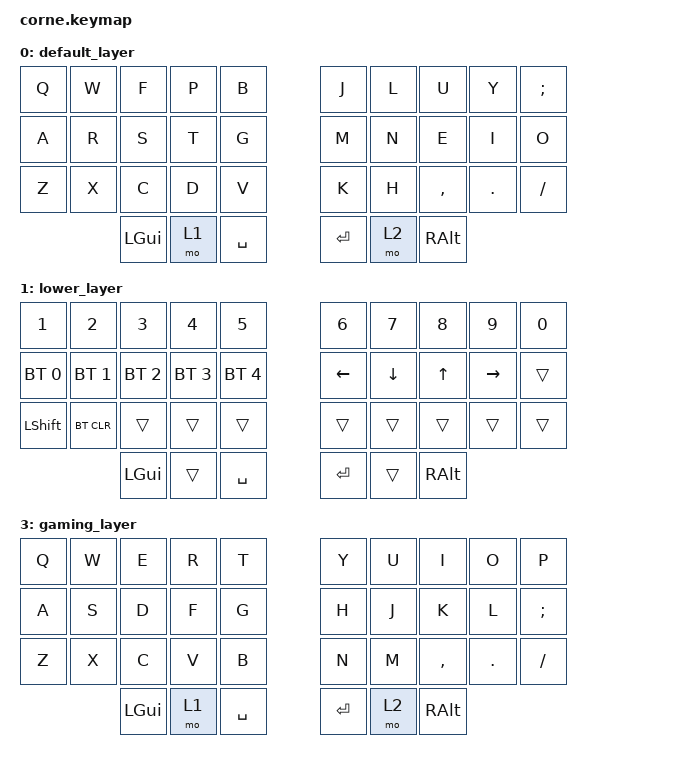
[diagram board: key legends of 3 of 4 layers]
/*
 * Copyright (c) 2020 The ZMK Contributors
 *
 * SPDX-License-Identifier: MIT
 */

#include <behaviors.dtsi>
#include <dt-bindings/zmk/keys.h>
#include <dt-bindings/zmk/bt.h>

/ {
        chosen { 
                zmk,physical-layout = &foostan_corne_5col_layout; };
        keymap {
                compatible = "zmk,keymap";

                default_layer {
// -----------------------------------------------------------------------------------------
// |  Q  |  W  |  F  |  P  |  B  |   |  J  |  L   |  U  |  Y  |  ;  |
// |  A  |  R  |  S  |  T  |  G  |   |  M  |  N   |  E  |  I  |  O  |
// |  Z  |  X  |  C  |  D  |  V  |   |  K  |  H   |  ,  |  .  |  /  |
//             | GUI | LWR | SPC |   | ENT | RSE  | ALT |
                        bindings = <
     &kp Q &kp W &kp F &kp P &kp B   &kp J &kp L  &kp U     &kp Y   &kp SEMI
     &kp A &kp R &kp S &kp T &kp G   &kp M &kp N  &kp E     &kp I   &kp O
     &kp Z &kp X &kp C &kp D &kp V   &kp K &kp H  &kp COMMA &kp DOT &kp FSLH
          &kp LGUI &mo 1 &kp SPACE   &kp RET &mo 2 &kp RALT
                        >;
                };
                lower_layer {
// -----------------------------------------------------------------------------------------
// |  1   |  2  |  3  |  4  |  5  |     |   |  6  |  7  |  8  |  9  |  0  |
// | BTCLR| BT1 | BT2 | BT3 | BT4 | BT5 |   | LFT | DWN |  UP | RGT |     |
// | SHFT |     |     |     |     |     |   |     |     |     |     |     |
//                    | GUI |     | SPC |   | ENT |     | ALT |
                        bindings = <
   &kp N1       &kp N2       &kp N3       &kp N4       &kp N5         &kp N6   &kp N7   &kp N8 &kp N9    &kp N0 
   &bt BT_SEL 0 &bt BT_SEL 1 &bt BT_SEL 2 &bt BT_SEL 3 &bt BT_SEL 4   &kp LEFT &kp DOWN &kp UP &kp RIGHT &trans
   &kp LSHIFT	&bt BT_CLR         &trans       &trans       &trans       &trans         &trans   &trans   &trans &trans
                                    &kp LGUI     &trans       &kp SPACE      &kp RET  &trans   &kp RALT
                        >;
                };

                raise_layer {
// -----------------------------------------------------------------------------------------
// |  !  |  @  |  #  |  $  |  %  |   |  ^  |  &  |  *  |  (  |  )  |
// |     |     |     |     |     |   |  -  |  =  |  [  |  ]  |  \  |
// |     |     |     |     |     |   |  _  |  +  |  {  |  }  | "|" |
//                    | GUI |     | SPC |   | ENT |     | ALT |
                        bindings = <
   &kp EXCL &kp AT &kp HASH &kp DLLR &kp PRCNT   &kp CARET &kp AMPS  &kp ASTRK &kp LPAR &kp RPAR &kp BSPC
   &trans   &trans &trans   &trans   &trans      &kp MINUS &kp EQUAL &kp LBKT  &kp RBKT &kp BSLH &kp GRAVE
   &trans   &trans &trans   &trans   &trans      &kp UNDER &kp PLUS  &kp LBRC  &kp RBRC &kp PIPE &kp TILDE
                   &kp LGUI &trans   &kp SPACE   &kp RET   &trans    &kp RALT
                        >;
                };
                gaming_layer {
// -----------------------------------------------------------------------------------------
// |  Q  |  W  |  E  |  R  |  T  |   |  Y  |  U   |  I  |  O  |  P  |
// |  A  |  S  |  D  |  F  |  G  |   |  H  |  J   |  K  |  L  |  ;  |
// |  Z  |  X  |  C  |  V  |  B  |   |  N  |  M   |  ,  |  .  |  /  |
//             | GUI | LWR | SPC |   | ENT | RSE  | ALT |
                        bindings = <
     &kp Q &kp W &kp E &kp R &kp T   &kp Y &kp U  &kp I     &kp O   &kp P
     &kp A &kp S &kp D &kp F &kp G   &kp H &kp J  &kp K     &kp L   &kp SEMI
     &kp Z &kp X &kp C &kp V &kp B   &kp N &kp M  &kp COMMA &kp DOT &kp FSLH
          &kp LGUI &mo 1 &kp SPACE   &kp RET &mo 2 &kp RALT
                        >;
                };
        };
};
